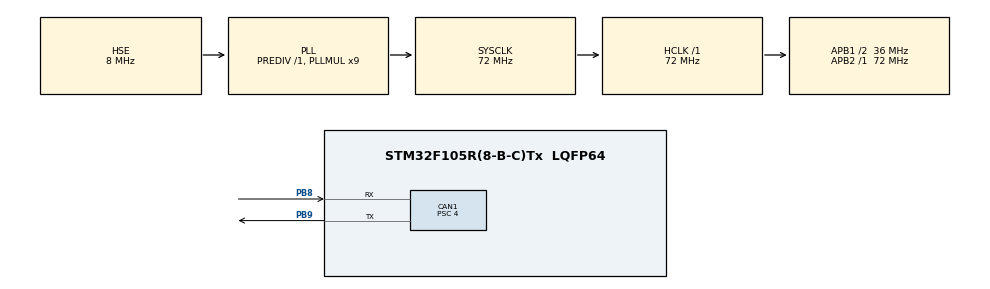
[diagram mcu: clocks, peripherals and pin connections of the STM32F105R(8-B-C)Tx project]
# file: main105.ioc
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CAN1.BS1=CAN_BS1_15TQ
CAN1.BS2=CAN_BS2_2TQ
CAN1.CalculateBaudRate=500000
CAN1.CalculateTimeBit=2000
CAN1.CalculateTimeQuantum=111.11111111111111
CAN1.Prescaler=4
Mcu.Family=STM32F1
Mcu.Name=STM32F105R(8-B-C)Tx
Mcu.Package=LQFP64
NVIC.CAN1_RX0_IRQn=true\:0\:0\:false\:false\:true\:true\:true\:true
NVIC.CAN1_TX_IRQn=true\:0\:0\:false\:false\:true\:true\:true\:true
NVIC.PriorityGroup=NVIC_PRIORITYGROUP_4
PA13.Mode=Serial_Wire
PA13.Signal=SYS_JTMS-SWDIO
PA14.Mode=Serial_Wire
PA14.Signal=SYS_JTCK-SWCLK
PB8.Mode=CAN_Activate
PB8.Signal=CAN1_RX
PB9.Mode=CAN_Activate
PB9.Signal=CAN1_TX
PD0-OSC_IN.Mode=HSE-External-Oscillator
PD0-OSC_IN.Signal=RCC_OSC_IN
PD1-OSC_OUT.Mode=HSE-External-Oscillator
PD1-OSC_OUT.Signal=RCC_OSC_OUT
ProjectManager.HeapSize=0x200
ProjectManager.StackSize=0x400
ProjectManager.TargetToolchain=MDK-ARM V5.32
RCC.AHBFreq_Value=72000000
RCC.APB1CLKDivider=RCC_HCLK_DIV2
RCC.APB1Freq_Value=36000000
RCC.APB1TimFreq_Value=72000000
RCC.APB2Freq_Value=72000000
RCC.APB2TimFreq_Value=72000000
RCC.HCLKFreq_Value=72000000
RCC.PLLMUL=RCC_PLL_MUL9
RCC.PLLSourceVirtual=RCC_PLLSOURCE_HSE
RCC.SYSCLKFreq_VALUE=72000000
RCC.SYSCLKSource=RCC_SYSCLKSOURCE_PLLCLK
RCC.USBFreq_Value=48000000
board=custom

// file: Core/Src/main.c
/* USER CODE BEGIN Header */
/**
  ******************************************************************************
  * @file           : main.c
  * @brief          : Main program body
  ******************************************************************************
  * @attention
  *
  * Copyright (c) 2022 STMicroelectronics.
  * All rights reserved.
  *
  * This software is licensed under terms that can be found in the LICENSE file
  * in the root directory of this software component.
  * If no LICENSE file comes with this software, it is provided AS-IS.
  *
  ******************************************************************************
  */
#include "brt_utc.h"
/* USER CODE END Header */
#include "main.h"

 CAN_HandleTypeDef hcan1;

void SystemClock_Config(void);
static void MX_GPIO_Init(void);
static void MX_CAN1_Init(void);

int main(void)
{
  /* USER CODE BEGIN 1 */
    ChangeVectorTable();
	uint8_t data[8] = "govnico";
  /* USER CODE END 1 */

  /* MCU Configuration--------------------------------------------------------*/

  /* Reset of all peripherals, Initializes the Flash interface and the Systick. */
  HAL_Init();

  /* Configure the system clock */
  SystemClock_Config();

  /* Initialize all configured peripherals */
  MX_GPIO_Init();
  MX_CAN1_Init();

  /* Infinite loop */
    while (1)
    {

    /* USER CODE BEGIN 3 */
		HAL_CAN_AddTxMessage(&hcan1, &pTxHeader, data, &TxMailbox);
		HAL_Delay(500);
    }
  /* USER CODE END 3 */
}

void SystemClock_Config(void)
{
  RCC_OscInitTypeDef RCC_OscInitStruct = {0};
  RCC_ClkInitTypeDef RCC_ClkInitStruct = {0};

  /** Initializes the RCC Oscillators according to the specified parameters
  * in the RCC_OscInitTypeDef structure.
  */
  RCC_OscInitStruct.OscillatorType = RCC_OSCILLATORTYPE_HSE;
  RCC_OscInitStruct.HSEState = RCC_HSE_ON;
  RCC_OscInitStruct.HSEPredivValue = RCC_HSE_PREDIV_DIV1;
  RCC_OscInitStruct.HSIState = RCC_HSI_ON;
  RCC_OscInitStruct.Prediv1Source = RCC_PREDIV1_SOURCE_HSE;
  RCC_OscInitStruct.PLL.PLLState = RCC_PLL_ON;
  RCC_OscInitStruct.PLL.PLLSource = RCC_PLLSOURCE_HSE;
  RCC_OscInitStruct.PLL.PLLMUL = RCC_PLL_MUL9;
  RCC_OscInitStruct.PLL2.PLL2State = RCC_PLL_NONE;
  if (HAL_RCC_OscConfig(&RCC_OscInitStruct) != HAL_OK)
  {
    Error_Handler();
  }

  /** Initializes the CPU, AHB and APB buses clocks
  */
  RCC_ClkInitStruct.ClockType = RCC_CLOCKTYPE_HCLK|RCC_CLOCKTYPE_SYSCLK
                              |RCC_CLOCKTYPE_PCLK1|RCC_CLOCKTYPE_PCLK2;
  RCC_ClkInitStruct.SYSCLKSource = RCC_SYSCLKSOURCE_PLLCLK;
  RCC_ClkInitStruct.AHBCLKDivider = RCC_SYSCLK_DIV1;
  RCC_ClkInitStruct.APB1CLKDivider = RCC_HCLK_DIV2;
  RCC_ClkInitStruct.APB2CLKDivider = RCC_HCLK_DIV1;

  if (HAL_RCC_ClockConfig(&RCC_ClkInitStruct, FLASH_LATENCY_2) != HAL_OK)
  {
    Error_Handler();
  }

  /** Configure the Systick interrupt time
  */
  __HAL_RCC_PLLI2S_ENABLE();
}

static void MX_CAN1_Init(void)
{

  hcan1.Instance = CAN1;
  hcan1.Init.Prescaler = 4;
  hcan1.Init.Mode = CAN_MODE_NORMAL;
  hcan1.Init.SyncJumpWidth = CAN_SJW_1TQ;
  hcan1.Init.TimeSeg1 = CAN_BS1_15TQ;
  hcan1.Init.TimeSeg2 = CAN_BS2_2TQ;
  hcan1.Init.TimeTriggeredMode = DISABLE;
  hcan1.Init.AutoBusOff = DISABLE;
  hcan1.Init.AutoWakeUp = DISABLE;
  hcan1.Init.AutoRetransmission = DISABLE;
  hcan1.Init.ReceiveFifoLocked = DISABLE;
  hcan1.Init.TransmitFifoPriority = DISABLE;
  if (HAL_CAN_Init(&hcan1) != HAL_OK)
  {
    Error_Handler();
  }
  /* USER CODE BEGIN CAN1_Init 2 */
    CANBusStart();
  /* USER CODE END CAN1_Init 2 */

}

static void MX_GPIO_Init(void)
{

  /* GPIO Ports Clock Enable */
  __HAL_RCC_GPIOD_CLK_ENABLE();
  __HAL_RCC_GPIOA_CLK_ENABLE();
  __HAL_RCC_GPIOB_CLK_ENABLE();

}

/* USER CODE BEGIN 4 */
void HAL_CAN_RxFifo0MsgPendingCallback(CAN_HandleTypeDef *hcan)
{
    HAL_CAN_GetRxMessage(hcan, CAN_RX_FIFO0, &pRxHeader, RX_data);

    if (pRxHeader.StdId == DEVICE_ID)
    {
        if (RX_data[0] == 'S' && RX_data[1] == 'T' && RX_data[2] == 'A' && RX_data[3] == 'R' && RX_data[4] == 'T')
        {
            StartUpdate();
        }
    }
    else
    {
        //	your code...
    }
}

void HAL_CAN_TxMailbox0CompleteCallback(CAN_HandleTypeDef*hcan) {}
/* USER CODE END 4 */

void Error_Handler(void)
{
    __disable_irq();
    while (1)
    {
    }
}
